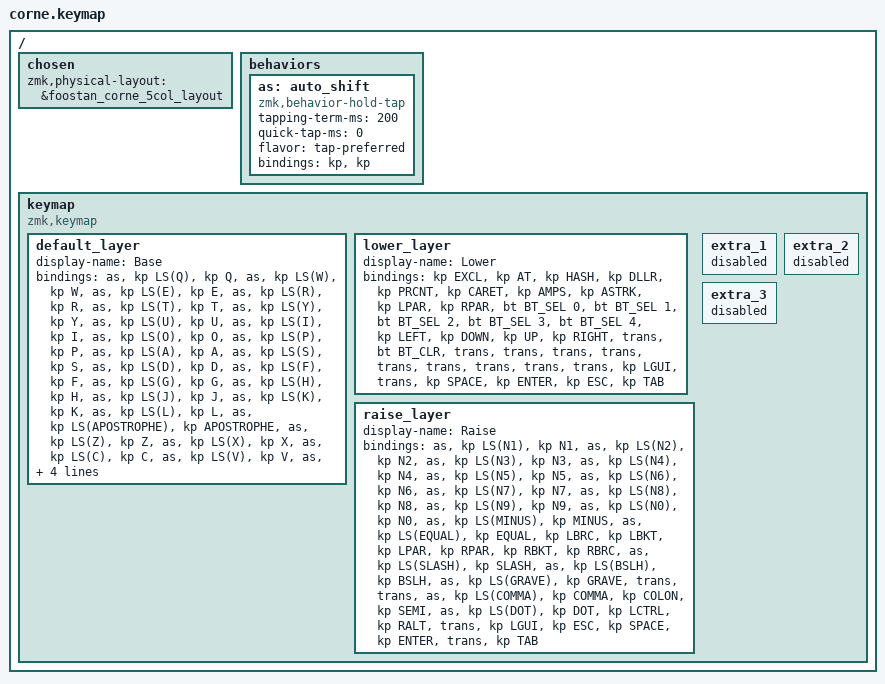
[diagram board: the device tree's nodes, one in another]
/*
 * Copyright (c) 2020 The ZMK Contributors
 *
 * SPDX-License-Identifier: MIT
 */

#include <behaviors.dtsi>
#include <dt-bindings/zmk/keys.h>
#include <dt-bindings/zmk/bt.h>

/ {
    chosen {
        zmk,physical-layout = &foostan_corne_5col_layout;
    };

    behaviors {
        as: auto_shift {
            compatible = "zmk,behavior-hold-tap";
            #binding-cells = <2>;
            tapping-term-ms = <200>;
            quick-tap-ms = <0>;
            flavor = "tap-preferred";
            bindings = <&kp>, <&kp>;
        };
    };

    keymap {
        compatible = "zmk,keymap";

        default_layer {
            display-name = "Base";
            bindings = <
                &as &kp LS(Q) &kp Q   &as &kp LS(W) &kp W   &as &kp LS(E) &kp E   &as &kp LS(R) &kp R   &as &kp LS(T) &kp T
                &as &kp LS(Y) &kp Y   &as &kp LS(U) &kp U   &as &kp LS(I) &kp I   &as &kp LS(O) &kp O   &as &kp LS(P) &kp P

                &as &kp LS(A) &kp A   &as &kp LS(S) &kp S   &as &kp LS(D) &kp D   &as &kp LS(F) &kp F   &as &kp LS(G) &kp G
                &as &kp LS(H) &kp H   &as &kp LS(J) &kp J   &as &kp LS(K) &kp K   &as &kp LS(L) &kp L   &as &kp LS(APOSTROPHE) &kp APOSTROPHE

                &as &kp LS(Z) &kp Z   &as &kp LS(X) &kp X   &as &kp LS(C) &kp C   &as &kp LS(V) &kp V   &as &kp LS(B) &kp B
                &as &kp LS(N) &kp N   &as &kp LS(M) &kp M   &kp LCTL       &kp RALT              &as &kp LS(DOT) &kp DOT

                                &kp LGUI    &mo 1     &kp SPACE      &kp ENTER     &mo 2        &kp BSPC
            >;
        };

        lower_layer {
            display-name = "Lower";
            bindings = <
                &kp EXCL      &kp AT       &kp HASH     &kp DLLR     &kp PRCNT          &kp CARET    &kp AMPS  &kp ASTRK  &kp LPAR   &kp RPAR
                &bt BT_SEL 0  &bt BT_SEL 1 &bt BT_SEL 2 &bt BT_SEL 3 &bt BT_SEL 4       &kp LEFT     &kp DOWN  &kp UP     &kp RIGHT  &trans
                &bt BT_CLR    &trans       &trans       &trans       &trans             &trans       &trans    &trans     &trans     &trans
                               &kp LGUI    &trans       &kp SPACE    &kp ENTER          &kp ESC      &kp TAB
            >;
        };

        raise_layer {
            display-name = "Raise";
            bindings = <
                &as &kp LS(N1) &kp N1   &as &kp LS(N2) &kp N2   &as &kp LS(N3) &kp N3   &as &kp LS(N4) &kp N4   &as &kp LS(N5) &kp N5
                &as &kp LS(N6) &kp N6   &as &kp LS(N7) &kp N7   &as &kp LS(N8) &kp N8   &as &kp LS(N9) &kp N9   &as &kp LS(N0) &kp N0

                &as &kp LS(MINUS) &kp MINUS   &as &kp LS(EQUAL) &kp EQUAL   &kp LBRC   &kp LBKT   &kp LPAR
                &kp RPAR          &kp RBKT    &kp RBRC         &as &kp LS(SLASH) &kp SLASH     &as &kp LS(BSLH) &kp BSLH

                &as &kp LS(GRAVE) &kp GRAVE   &trans           &trans       &as &kp LS(COMMA) &kp COMMA     &kp COLON
                &kp SEMI          &as &kp LS(DOT) &kp DOT       &kp LCTRL     &kp RALT        &trans

                             &kp LGUI   &kp ESC   &kp SPACE     &kp ENTER     &trans          &kp TAB
            >;
        };

        extra_1 {
            status = "reserved";
        };

        extra_2 {
            status = "reserved";
        };

        extra_3 {
            status = "reserved";
        };
    };
};
